# HDSC_HC32M424 register map
Vendor: HDSC; Series: ARMCM4; File version: 1.0
CPU: CM4 r0p1, little endian, MPU, FPU, 4 interrupt priority bits
Registers are 32-bit, read-write, reset 0x0 unless marked. A register's access mark holds for its fields unless they carry their own. Offsets are from the block's base; [hi:lo] are bit positions; {n}, {i} and the like mark numbered series.

## CMP1 — desc CMP
Base 0x4004A000
Same registers: CMP2 0x4004A010, CMP3 0x4004A020, CMP4 0x4004A030
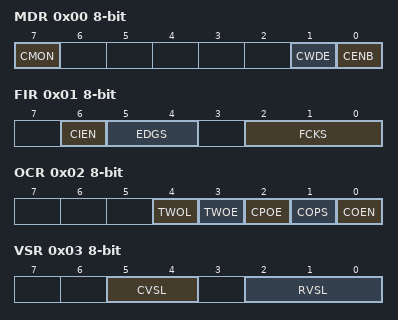
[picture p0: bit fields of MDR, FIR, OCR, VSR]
0x00 MDR 8-bit
  [7] CMON ro, [1] CWDE, [0] CENB
0x01 FIR 8-bit
  [6] CIEN, [5:4] EDGS, [2:0] FCKS
0x02 OCR 8-bit
  [4] TWOL, [3] TWOE, [2] CPOE, [1] COPS, [0] COEN
0x03 VSR 8-bit
  [5:4] CVSL, [2:0] RVSL
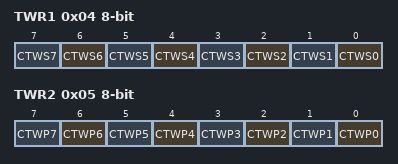
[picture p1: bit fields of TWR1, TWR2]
0x04 TWR1 8-bit
  [n] CTWS{n} (n=0..7)
0x05 TWR2 8-bit
  [n] CTWP{n} (n=0..7)

## CMPCR
Base 0x4004A100
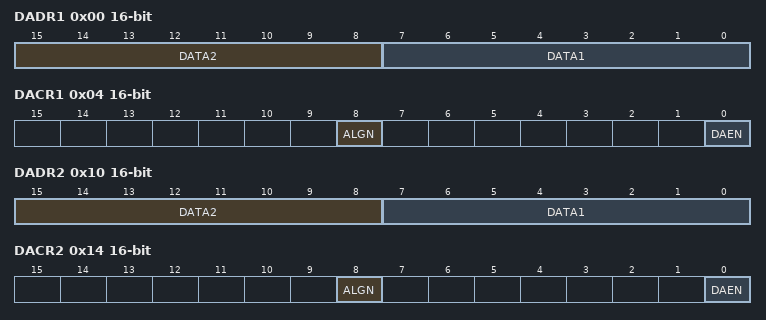
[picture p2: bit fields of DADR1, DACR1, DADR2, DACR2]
0x00 DADR1 16-bit
  [15:8] DATA2, [7:0] DATA1
0x04 DACR1 16-bit
  [8] ALGN, [0] DAEN
0x08 DAOC1 8-bit
  [0] DAODIS
0x10 DADR2 16-bit
  [15:8] DATA2, [7:0] DATA1
0x14 DACR2 16-bit
  [8] ALGN, [0] DAEN
0x18 DAOC2 8-bit
  [0] DAODIS

## CMU
Base 0x40054400
0x00 ADCKSEL 8-bit
  [2:0] ADCKSEL
0x04 XTALSTDSR 8-bit
  [0] XTALSTDF
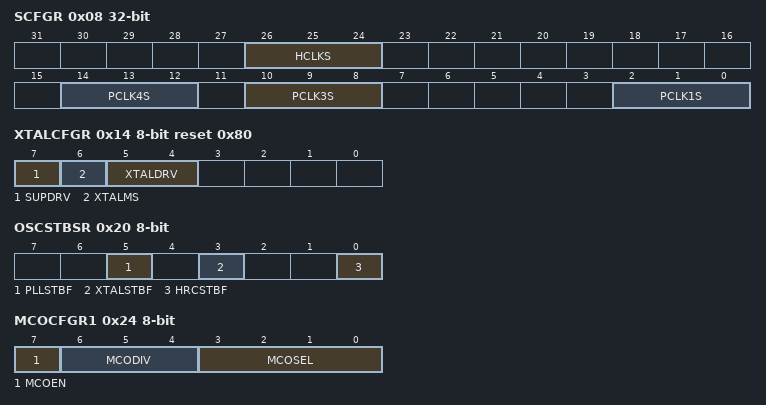
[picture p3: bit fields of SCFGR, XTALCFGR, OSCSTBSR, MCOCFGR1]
0x08 SCFGR
  [26:24] HCLKS, [14:12] PCLK4S, [10:8] PCLK3S, [2:0] PCLK1S
0x0C CKSWR 8-bit
  [2:0] CKSW
0x10 XTALCR 8-bit reset 0x1
  [0] XTALSTP
0x14 XTALCFGR 8-bit reset 0x80
  [7] SUPDRV, [6] XTALMS, [5:4] XTALDRV
0x15 XTALSTBCR 8-bit
  [2:0] XTALSTB
0x18 HRCCR 8-bit
  [0] HRCSTP
0x20 OSCSTBSR 8-bit ro
  [5] PLLSTBF, [3] XTALSTBF, [0] HRCSTBF
0x24 MCOCFGR1 8-bit
  [7] MCOEN, [6:4] MCODIV, [3:0] MCOSEL
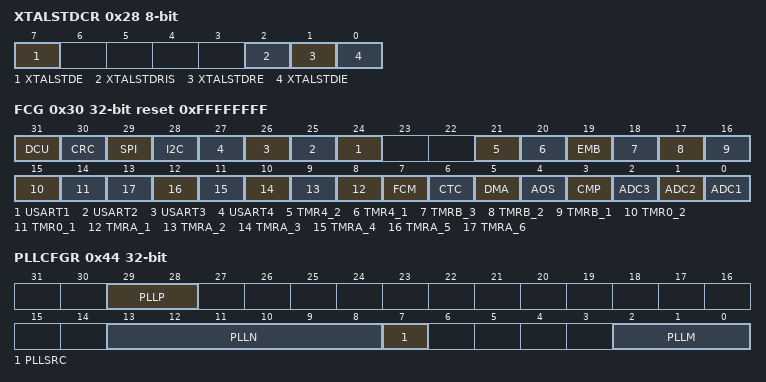
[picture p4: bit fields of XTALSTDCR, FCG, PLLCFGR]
0x28 XTALSTDCR 8-bit
  [7] XTALSTDE, [2] XTALSTDRIS, [1] XTALSTDRE, [0] XTALSTDIE
0x30 FCG reset 0xFFFFFFFF
  [31] DCU, [30] CRC, [29] SPI, [28] I2C, [n+23] USART{n} (n=1..4), [21] TMR4_2, [20] TMR4_1, [19] EMB, [18] TMRB_3, [17] TMRB_2, [16] TMRB_1, [15] TMR0_2, [14] TMR0_1, [n+7] TMRA_{n} (n=1..6), [7] FCM, [6] CTC, [5] DMA, [4] AOS, [3] CMP, [2] ADC3, [1] ADC2, [0] ADC1
0x3C LRCCR 8-bit
  [0] LRCSTP
0x40 MRCCR 8-bit
  [0] MRCSTP
0x44 PLLCFGR
  [29:28] PLLP, [13:8] PLLN, [7] PLLSRC, [2:0] PLLM
0x48 PLLCR 8-bit reset 0x1
  [0] PLLOFF

## CRC
Base 0x40050400
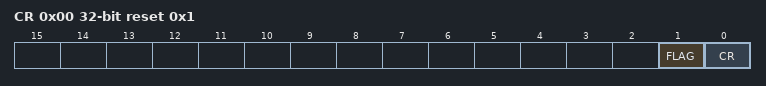
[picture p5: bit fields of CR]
0x00 CR reset 0x1
  [1] FLAG, [0] CR
0x04 RESLT
{0x80+4i} DAT{i} (i=0..31)

## CTC
Base 0x40040000
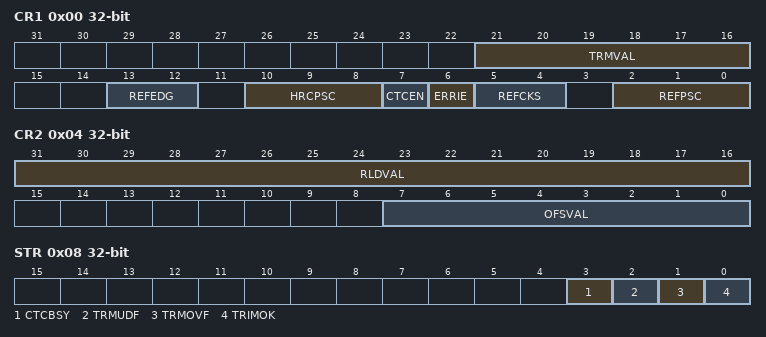
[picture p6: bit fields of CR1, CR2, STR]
0x00 CR1 (reset mask 0x3F1FF7)
  [21:16] TRMVAL, [13:12] REFEDG, [10:8] HRCPSC, [7] CTCEN, [6] ERRIE, [5:4] REFCKS, [2:0] REFPSC
0x04 CR2
  [31:16] RLDVAL, [7:0] OFSVAL
0x08 STR ro
  [3] CTCBSY, [2] TRMUDF, [1] TRMOVF, [0] TRIMOK
0x0C CNT 16-bit ro
  [15:0] CTCCNT

## DBGC
Base 0xE0042000
{0x0+4i} DBG_AUTHID{i} (i=0..2)
0x0C DBG_RESV0
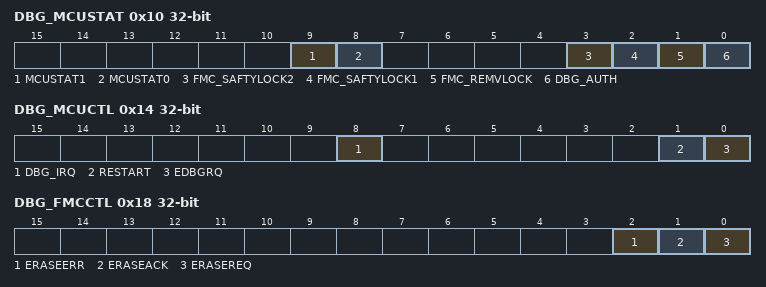
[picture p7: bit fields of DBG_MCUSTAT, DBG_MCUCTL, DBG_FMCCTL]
0x10 DBG_MCUSTAT
  [9] MCUSTAT1, [8] MCUSTAT0, [3] FMC_SAFTYLOCK2, [2] FMC_SAFTYLOCK1, [1] FMC_REMVLOCK, [0] DBG_AUTH
0x14 DBG_MCUCTL
  [8] DBG_IRQ, [1] RESTART, [0] EDBGRQ
0x18 DBG_FMCCTL
  [2] ERASEERR, [1] ERASEACK, [0] ERASEREQ

## DCU
Base 0x40052000
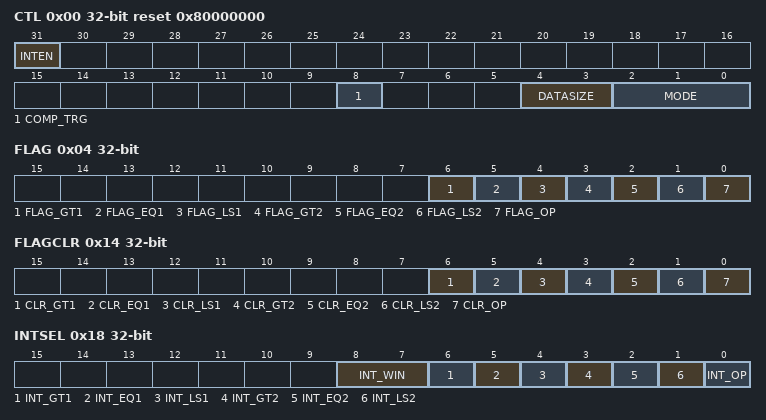
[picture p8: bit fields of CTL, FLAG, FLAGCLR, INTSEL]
0x00 CTL reset 0x80000000
  [31] INTEN, [8] COMP_TRG, [4:3] DATASIZE, [2:0] MODE
0x04 FLAG ro
  [6] FLAG_GT1, [5] FLAG_EQ1, [4] FLAG_LS1, [3] FLAG_GT2, [2] FLAG_EQ2, [1] FLAG_LS2, [0] FLAG_OP
{0x8+4i} DATA{i} (i=0..2)
0x14 FLAGCLR wo
  [6] CLR_GT1, [5] CLR_EQ1, [4] CLR_LS1, [3] CLR_GT2, [2] CLR_EQ2, [1] CLR_LS2, [0] CLR_OP
0x18 INTSEL
  [8:7] INT_WIN, [6] INT_GT1, [5] INT_EQ1, [4] INT_LS1, [3] INT_GT2, [2] INT_EQ2, [1] INT_LS2, [0] INT_OP

## DMA
Base 0x40053000
0x00 EN
  [0] EN
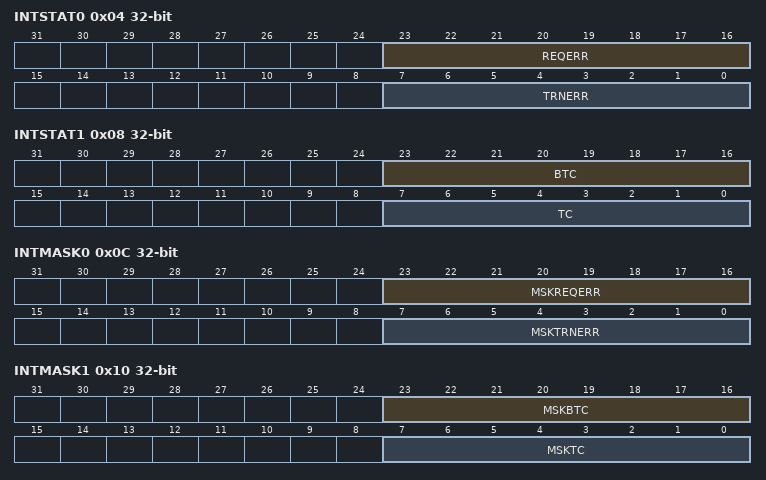
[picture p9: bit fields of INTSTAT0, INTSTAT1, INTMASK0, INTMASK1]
0x04 INTSTAT0 ro
  [23:16] REQERR, [7:0] TRNERR
0x08 INTSTAT1 ro
  [23:16] BTC, [7:0] TC
0x0C INTMASK0
  [23:16] MSKREQERR, [7:0] MSKTRNERR
0x10 INTMASK1
  [23:16] MSKBTC, [7:0] MSKTC
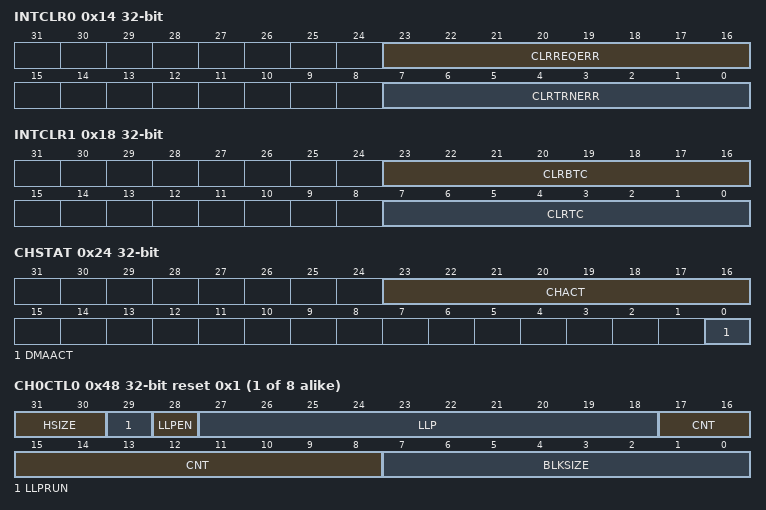
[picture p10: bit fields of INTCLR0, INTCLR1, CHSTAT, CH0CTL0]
0x14 INTCLR0 wo
  [23:16] CLRREQERR, [7:0] CLRTRNERR
0x18 INTCLR1 wo
  [23:16] CLRBTC, [7:0] CLRTC
0x1C CHEN
  [7:0] CHEN
0x24 CHSTAT ro
  [23:16] CHACT, [0] DMAACT
0x30 BASE1_LLP reset 0x20000000
  [31:14] LLP
0x34 BASE2_LLP
  [31:14] LLP
0x38 CHENCLR wo
  [7:0] CHENCLR
{0x40+0x40*i} SAR{i} (i=0..7)
{0x44+0x40*i} DAR{i} (i=0..7)
{0x48+0x40*i} CH{i}CTL0 reset 0x1 (i=0..7)
  [31:30] HSIZE, [29] LLPRUN, [28] LLPEN, [27:18] LLP, [17:8] CNT, [7:0] BLKSIZE
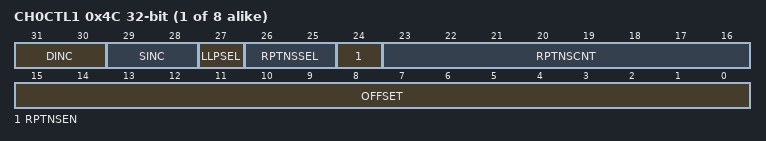
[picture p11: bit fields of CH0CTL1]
{0x4C+0x40*i} CH{i}CTL1 (i=0..7)
  [31:30] DINC, [29:28] SINC, [27] LLPSEL, [26:25] RPTNSSEL, [24] RPTNSEN, [23:16] RPTNSCNT, [15:0] OFFSET
